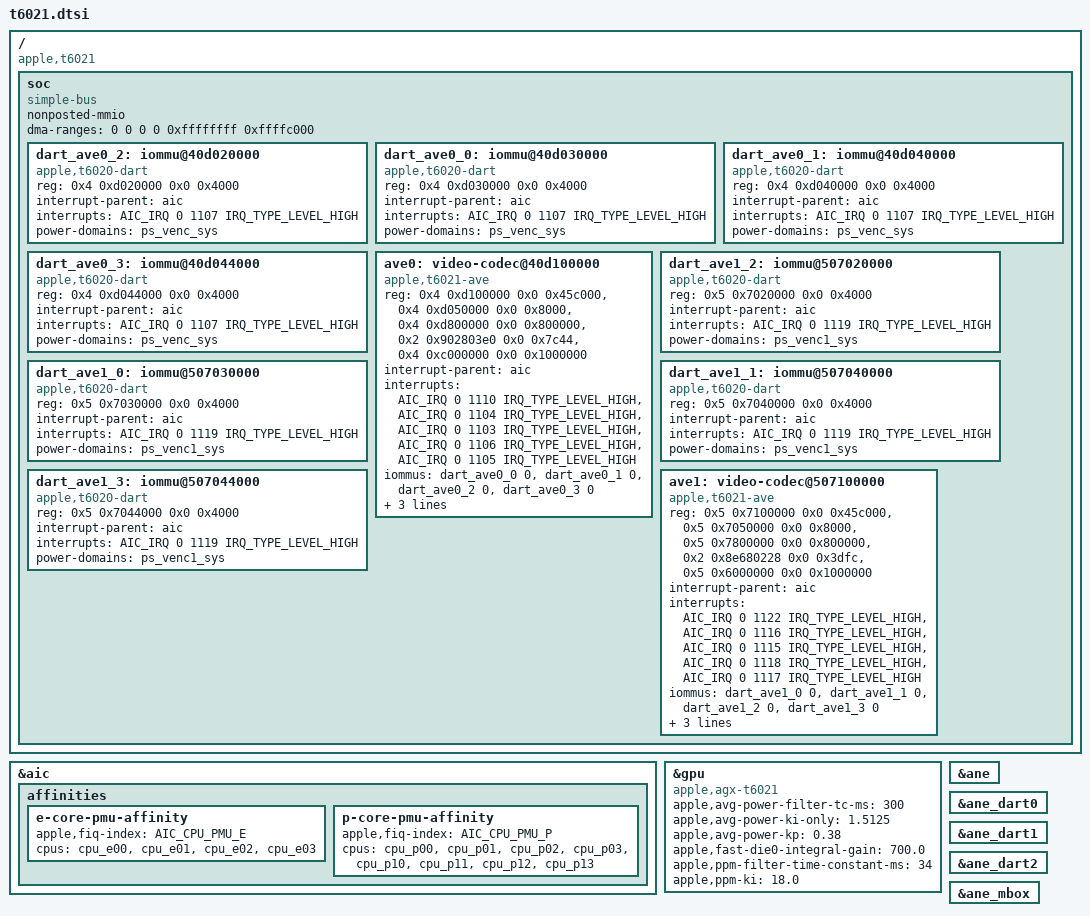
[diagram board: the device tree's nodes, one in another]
// SPDX-License-Identifier: GPL-2.0+ OR MIT
/*
 * Apple T6021 "M2 Max" SoC
 *
 * Other names: H14J, "Rhodes"
 *
 * Copyright The Asahi Linux Contributors
 */

#include <dt-bindings/gpio/gpio.h>
#include <dt-bindings/interrupt-controller/apple-aic.h>
#include <dt-bindings/interrupt-controller/irq.h>
#include <dt-bindings/pinctrl/apple.h>
#include <dt-bindings/phy/phy.h>
#include <dt-bindings/spmi/spmi.h>

#include "multi-die-cpp.h"

#ifndef GPU_REPEAT
# define GPU_REPEAT(x) <x x x x>
#endif
#ifndef GPU_DIE_REPEAT
# define GPU_DIE_REPEAT(x) <x>
#endif

#define APPLE_T602X_NON_ULTRA

#include "t602x-common.dtsi"

/ {
	compatible = "apple,t6021", "apple,arm-platform";

	soc {
		compatible = "simple-bus";
		#address-cells = <2>;
		#size-cells = <2>;

		ranges;
		nonposted-mmio;
		/* Required to get >32-bit DMA via DARTs */
		dma-ranges = <0 0 0 0 0xffffffff 0xffffc000>;

		// filled via templated includes at the end of the file
	};
};

#define DIE
#define DIE_NO 0
#define SOC_NODE {/soc}

#include "t602x-die0.dtsi"
#include "t602x-dieX.dtsi"
#include "t602x-nvme.dtsi"
#include "t602x-gpio-pins.dtsi"
#include "t602x-pmgr.dtsi"

#undef DIE
#undef DIE_NO


&aic {
	affinities {
		e-core-pmu-affinity {
			apple,fiq-index = <AIC_CPU_PMU_E>;
			cpus = <&cpu_e00 &cpu_e01 &cpu_e02 &cpu_e03>;
		};

		p-core-pmu-affinity {
			apple,fiq-index = <AIC_CPU_PMU_P>;
			cpus = <&cpu_p00 &cpu_p01 &cpu_p02 &cpu_p03
				&cpu_p10 &cpu_p11 &cpu_p12 &cpu_p13>;
		};
	};
};

&gpu {
	compatible = "apple,agx-t6021", "apple,agx-g14x", "apple,agx-g14c", "apple,agx-g14s";

	apple,avg-power-filter-tc-ms = <300>;
	apple,avg-power-ki-only = <1.5125>;
	apple,avg-power-kp = <0.38>;
	apple,fast-die0-integral-gain = <700.0>;
	apple,ppm-filter-time-constant-ms = <34>;
	apple,ppm-ki = <18.0>;
};

#include "hwmon-common.dtsi"

/*
 * The ANE has run on the M2 Pro and the M2 Max, so enable it here with its
 * mailbox and DARTs. t6020.dtsi includes this file.
 */
&ane {
	status = "okay";
};

&ane_dart0 {
	status = "okay";
};

&ane_dart1 {
	status = "okay";
};

&ane_dart2 {
	status = "okay";
};

&ane_mbox {
	status = "okay";
};

/*
 * M2 Max video encoders. Register layout from the aurora-silicon
 * t6021-peripherals description. Firmware text and data are apple,asc-mem
 * reservations the bootloader attaches as memory-region; this tree does
 * not invent those physical addresses. Both instances use the t6021
 * variant (the M2 / 6070.11.1 contract).
 */
&{/soc} {
	dart_ave0_2: iommu@40d020000 {
		compatible = "apple,t6020-dart", "apple,t8110-dart";
		reg = <0x4 0xd020000 0x0 0x4000>;
		interrupt-parent = <&aic>;
		interrupts = <AIC_IRQ 0 1107 IRQ_TYPE_LEVEL_HIGH>;
		power-domains = <&ps_venc_sys>;
		#iommu-cells = <1>;
	};

	dart_ave0_0: iommu@40d030000 {
		compatible = "apple,t6020-dart", "apple,t8110-dart";
		reg = <0x4 0xd030000 0x0 0x4000>;
		interrupt-parent = <&aic>;
		interrupts = <AIC_IRQ 0 1107 IRQ_TYPE_LEVEL_HIGH>;
		power-domains = <&ps_venc_sys>;
		#iommu-cells = <1>;
	};

	dart_ave0_1: iommu@40d040000 {
		compatible = "apple,t6020-dart", "apple,t8110-dart";
		reg = <0x4 0xd040000 0x0 0x4000>;
		interrupt-parent = <&aic>;
		interrupts = <AIC_IRQ 0 1107 IRQ_TYPE_LEVEL_HIGH>;
		power-domains = <&ps_venc_sys>;
		#iommu-cells = <1>;
	};

	dart_ave0_3: iommu@40d044000 {
		compatible = "apple,t6020-dart", "apple,t8110-dart";
		reg = <0x4 0xd044000 0x0 0x4000>;
		interrupt-parent = <&aic>;
		interrupts = <AIC_IRQ 0 1107 IRQ_TYPE_LEVEL_HIGH>;
		power-domains = <&ps_venc_sys>;
		#iommu-cells = <1>;
	};

	ave0: video-codec@40d100000 {
		compatible = "apple,t6021-ave", "apple,ave";
		power-domain-names = "dma", "pipe4", "pipe5", "me0", "me1", "perf";
		reg-names = "codec", "mailbox", "coproc", "power-control", "fabric";
		reg = <0x4 0xd100000 0x0 0x45c000>,
		      <0x4 0xd050000 0x0 0x8000>,
		      <0x4 0xd800000 0x0 0x800000>,
		      <0x2 0x902803e0 0x0 0x7c44>,
		      <0x4 0xc000000 0x0 0x1000000>;
		interrupt-parent = <&aic>;
		interrupts = <AIC_IRQ 0 1110 IRQ_TYPE_LEVEL_HIGH>,
			     <AIC_IRQ 0 1104 IRQ_TYPE_LEVEL_HIGH>,
			     <AIC_IRQ 0 1103 IRQ_TYPE_LEVEL_HIGH>,
			     <AIC_IRQ 0 1106 IRQ_TYPE_LEVEL_HIGH>,
			     <AIC_IRQ 0 1105 IRQ_TYPE_LEVEL_HIGH>;
		iommus = <&dart_ave0_0 0>, <&dart_ave0_1 0>,
			 <&dart_ave0_2 0>, <&dart_ave0_3 0>;
		power-domains = <&ps_venc_dma>, <&ps_venc_pipe4>,
				<&ps_venc_pipe5>, <&ps_venc_me0>,
				<&ps_venc_me1>, <&ps_afr>;
	};

	dart_ave1_2: iommu@507020000 {
		compatible = "apple,t6020-dart", "apple,t8110-dart";
		reg = <0x5 0x7020000 0x0 0x4000>;
		interrupt-parent = <&aic>;
		interrupts = <AIC_IRQ 0 1119 IRQ_TYPE_LEVEL_HIGH>;
		power-domains = <&ps_venc1_sys>;
		#iommu-cells = <1>;
	};

	dart_ave1_0: iommu@507030000 {
		compatible = "apple,t6020-dart", "apple,t8110-dart";
		reg = <0x5 0x7030000 0x0 0x4000>;
		interrupt-parent = <&aic>;
		interrupts = <AIC_IRQ 0 1119 IRQ_TYPE_LEVEL_HIGH>;
		power-domains = <&ps_venc1_sys>;
		#iommu-cells = <1>;
	};

	dart_ave1_1: iommu@507040000 {
		compatible = "apple,t6020-dart", "apple,t8110-dart";
		reg = <0x5 0x7040000 0x0 0x4000>;
		interrupt-parent = <&aic>;
		interrupts = <AIC_IRQ 0 1119 IRQ_TYPE_LEVEL_HIGH>;
		power-domains = <&ps_venc1_sys>;
		#iommu-cells = <1>;
	};

	dart_ave1_3: iommu@507044000 {
		compatible = "apple,t6020-dart", "apple,t8110-dart";
		reg = <0x5 0x7044000 0x0 0x4000>;
		interrupt-parent = <&aic>;
		interrupts = <AIC_IRQ 0 1119 IRQ_TYPE_LEVEL_HIGH>;
		power-domains = <&ps_venc1_sys>;
		#iommu-cells = <1>;
	};

	ave1: video-codec@507100000 {
		compatible = "apple,t6021-ave", "apple,ave";
		power-domain-names = "dma", "pipe4", "pipe5", "me0", "me1", "perf";
		reg-names = "codec", "mailbox", "coproc", "power-control", "fabric";
		reg = <0x5 0x7100000 0x0 0x45c000>,
		      <0x5 0x7050000 0x0 0x8000>,
		      <0x5 0x7800000 0x0 0x800000>,
		      <0x2 0x8e680228 0x0 0x3dfc>,
		      <0x5 0x6000000 0x0 0x1000000>;
		interrupt-parent = <&aic>;
		interrupts = <AIC_IRQ 0 1122 IRQ_TYPE_LEVEL_HIGH>,
			     <AIC_IRQ 0 1116 IRQ_TYPE_LEVEL_HIGH>,
			     <AIC_IRQ 0 1115 IRQ_TYPE_LEVEL_HIGH>,
			     <AIC_IRQ 0 1118 IRQ_TYPE_LEVEL_HIGH>,
			     <AIC_IRQ 0 1117 IRQ_TYPE_LEVEL_HIGH>;
		iommus = <&dart_ave1_0 0>, <&dart_ave1_1 0>,
			 <&dart_ave1_2 0>, <&dart_ave1_3 0>;
		power-domains = <&ps_venc1_dma>, <&ps_venc1_pipe4>,
				<&ps_venc1_pipe5>, <&ps_venc1_me0>,
				<&ps_venc1_me1>, <&ps_afr>;
	};
};
